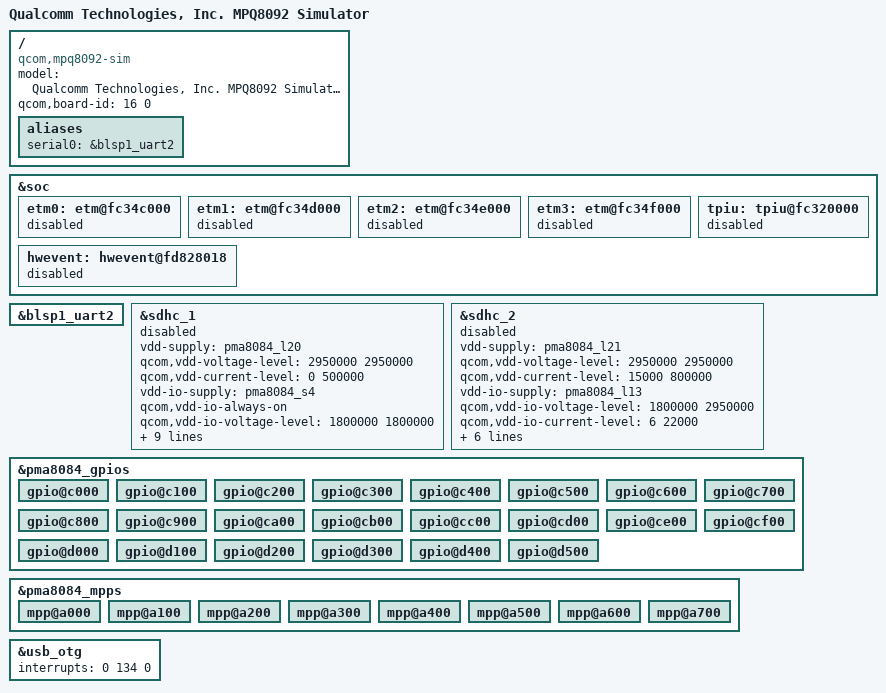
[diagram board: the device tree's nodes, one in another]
/* Copyright (c) 2012-2014, The Linux Foundation. All rights reserved.
 *
 * This program is free software; you can redistribute it and/or modify
 * it under the terms of the GNU General Public License version 2 and
 * only version 2 as published by the Free Software Foundation.
 *
 * This program is distributed in the hope that it will be useful,
 * but WITHOUT ANY WARRANTY; without even the implied warranty of
 * MERCHANTABILITY or FITNESS FOR A PARTICULAR PURPOSE.  See the
 * GNU General Public License for more details.
 */

/dts-v1/;

#include "mpq8092.dtsi"

/ {
	model = "Qualcomm Technologies, Inc. MPQ8092 Simulator";
	compatible = "qcom,mpq8092-sim", "qcom,mpq8092", "qcom,sim";
	qcom,board-id = <16 0>;

	aliases {
		serial0 = &blsp1_uart2;
	};
};

&soc {
	etm0: etm@fc34c000 {
		status = "disabled";
	};

	etm1: etm@fc34d000 {
		status = "disabled";
	};

	etm2: etm@fc34e000 {
		status = "disabled";
	};

	etm3: etm@fc34f000 {
		status = "disabled";
	};
	hwevent: hwevent@fd828018 {
		status = "disabled";
	};
	tpiu: tpiu@fc320000 {
		status = "disabled";
	};
};

&blsp1_uart2 {
	status = "ok";
};

&sdhc_1 {
	vdd-supply = <&pma8084_l20>;
	qcom,vdd-voltage-level = <2950000 2950000>;
	qcom,vdd-current-level = <0 500000>;

	vdd-io-supply = <&pma8084_s4>;
	qcom,vdd-io-always-on;
	qcom,vdd-io-voltage-level = <1800000 1800000>;
	qcom,vdd-io-current-level = <200 154000>;

	pinctrl-names = "active", "sleep";
	pinctrl-0 = <&sdc1_clk_on &sdc1_cmd_on &sdc1_data_on>;
	pinctrl-1 = <&sdc1_clk_off &sdc1_cmd_off &sdc1_data_off>;

	qcom,clk-rates = <400000 20000000 25000000 50000000 100000000 200000000>;
	qcom,bus-speed-mode = "HS200_1p8v", "DDR_1p8v";
	qcom,nonremovable;

	status = "disabled";
};

&sdhc_2 {
	vdd-supply = <&pma8084_l21>;
	qcom,vdd-voltage-level = <2950000 2950000>;
	qcom,vdd-current-level = <15000 800000>;

	vdd-io-supply = <&pma8084_l13>;
	qcom,vdd-io-voltage-level = <1800000 2950000>;
	qcom,vdd-io-current-level = <6 22000>;

	pinctrl-names = "active", "sleep";
	pinctrl-0 = <&sdc2_clk_on &sdc2_cmd_on &sdc2_data_on>;
	pinctrl-1 = <&sdc2_clk_off &sdc2_cmd_off &sdc2_data_off>;
	qcom,clk-rates = <400000 20000000 25000000 50000000 100000000 200000000>;

	status = "disabled";
};

&pma8084_gpios {
	gpio@c000 { /* GPIO 1 */
	};

	gpio@c100 { /* GPIO 2 */
	};

	gpio@c200 { /* GPIO 3 */
	};

	gpio@c300 { /* GPIO 4 */
	};

	gpio@c400 { /* GPIO 5 */
	};

	gpio@c500 { /* GPIO 6 */
	};

	gpio@c600 { /* GPIO 7 */
	};

	gpio@c700 { /* GPIO 8 */
	};

	gpio@c800 { /* GPIO 9 */
	};

	gpio@c900 { /* GPIO 10 */
	};

	gpio@ca00 { /* GPIO 11 */
	};

	gpio@cb00 { /* GPIO 12 */
	};

	gpio@cc00 { /* GPIO 13 */
	};

	gpio@cd00 { /* GPIO 14 */
	};

	gpio@ce00 { /* GPIO 15 */
	};

	gpio@cf00 { /* GPIO 16 */
	};

	gpio@d000 { /* GPIO 17 */
	};

	gpio@d100 { /* GPIO 18 */
	};

	gpio@d200 { /* GPIO 19 */
	};

	gpio@d300 { /* GPIO 20 */
	};

	gpio@d400 { /* GPIO 21 */
	};

	gpio@d500 { /* GPIO 22 */
	};
};

&pma8084_mpps {
	mpp@a000 { /* MPP 1 */
	};

	mpp@a100 { /* MPP 2 */
	};

	mpp@a200 { /* MPP 3 */
	};

	mpp@a300 { /* MPP 4 */
	};

	mpp@a400 { /* MPP5 */
	};

	mpp@a500 { /* MPP 6 */
	};

	mpp@a600 { /* MPP 7 */
	};

	mpp@a700 { /* MPP 8 */
	};
};

&usb_otg {
	interrupts = <0 134 0>;
	interrupt-names = "core_irq";
};
